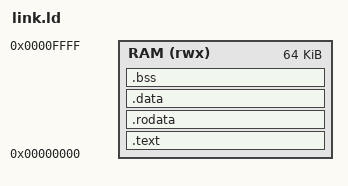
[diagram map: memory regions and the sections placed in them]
/* Single 64 KiB RAM at address 0, stack grows down from the top. */
OUTPUT_ARCH("riscv")
ENTRY(_start)

MEMORY { RAM (rwx) : ORIGIN = 0x00000000, LENGTH = 64K }

SECTIONS
{
  .text : { *(.text.init) *(.text .text.*) } > RAM
  .rodata : { *(.rodata .rodata.* .srodata .srodata.*) } > RAM
  .data : {
    *(.data .data.*)
    __global_pointer$ = . + 0x800;
    *(.sdata .sdata.*)
  } > RAM
  .bss (NOLOAD) : {
    __bss_start = .;
    *(.bss .bss.* .sbss .sbss.* COMMON)
    . = ALIGN(4);
    __bss_end = .;
  } > RAM
  __stack_top = ORIGIN(RAM) + LENGTH(RAM);
}
